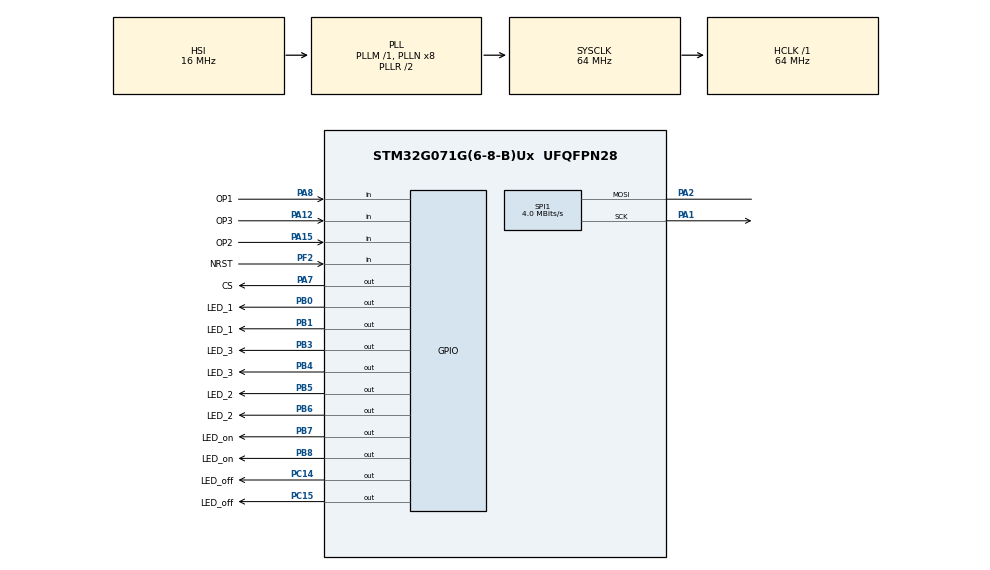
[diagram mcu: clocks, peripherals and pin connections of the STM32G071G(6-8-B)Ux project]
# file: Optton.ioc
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Dma.Request0=SPI1_TX
Dma.SPI1_TX.0.Direction=DMA_MEMORY_TO_PERIPH
Dma.SPI1_TX.0.EventEnable=DISABLE
Dma.SPI1_TX.0.Instance=DMA1_Channel1
Dma.SPI1_TX.0.MemDataAlignment=DMA_MDATAALIGN_BYTE
Dma.SPI1_TX.0.MemInc=DMA_MINC_ENABLE
Dma.SPI1_TX.0.Mode=DMA_NORMAL
Dma.SPI1_TX.0.PeriphDataAlignment=DMA_PDATAALIGN_BYTE
Dma.SPI1_TX.0.PeriphInc=DMA_PINC_DISABLE
Dma.SPI1_TX.0.Polarity=HAL_DMAMUX_REQ_GEN_RISING
Dma.SPI1_TX.0.Priority=DMA_PRIORITY_LOW
Dma.SPI1_TX.0.RequestNumber=1
Dma.SPI1_TX.0.SignalID=NONE
Dma.SPI1_TX.0.SyncEnable=DISABLE
Dma.SPI1_TX.0.SyncPolarity=HAL_DMAMUX_SYNC_NO_EVENT
Dma.SPI1_TX.0.SyncRequestNumber=1
Dma.SPI1_TX.0.SyncSignalID=NONE
FREERTOS.Tasks01=defaultTask,24,128,StartDefaultTask,Default,NULL,Dynamic,NULL,NULL;MCP23Task,24,128,StartTask02,Default,NULL,Dynamic,NULL,NULL
Mcu.Family=STM32G0
Mcu.Name=STM32G071G(6-8-B)Ux
Mcu.Package=UFQFPN28
NVIC.DMA1_Channel1_IRQn=true\:3\:0\:false\:false\:true\:true\:false\:true\:true
NVIC.SPI1_IRQn=true\:3\:0\:false\:false\:true\:true\:true\:true\:true
PA1.Mode=Simplex_Bidirectional_Master
PA1.Signal=SPI1_SCK
PA12\ [PA10].GPIO_Label=OP3
PA12\ [PA10].Signal=GPIO_Input
PA13.Mode=Serial_Wire
PA13.Signal=SYS_SWDIO
PA14-BOOT0.Mode=Serial_Wire
PA14-BOOT0.Signal=SYS_SWCLK
PA15.GPIO_Label=OP2
PA15.Signal=GPIO_Input
PA2.Mode=Simplex_Bidirectional_Master
PA2.Signal=SPI1_MOSI
PA7.GPIO_Label=CS
PA7.Signal=GPIO_Output
PA8.GPIO_Label=OP1
PA8.Signal=GPIO_Input
PB0.GPIO_Label=LED_1
PB0.Signal=GPIO_Output
PB1.GPIO_Label=LED_1
PB1.Signal=GPIO_Output
PB3.GPIO_Label=LED_3
PB3.Signal=GPIO_Output
PB4.GPIO_Label=LED_3
PB4.Signal=GPIO_Output
PB5.GPIO_Label=LED_2
PB5.Signal=GPIO_Output
PB6.GPIO_Label=LED_2
PB6.Signal=GPIO_Output
PB7.GPIO_Label=LED_on
PB7.Signal=GPIO_Output
PB8.GPIO_Label=LED_on
PB8.Signal=GPIO_Output
PC14-OSC32_IN\ (PC14).GPIO_Label=LED_off
PC14-OSC32_IN\ (PC14).Signal=GPIO_Output
PC15-OSC32_OUT\ (PC15).GPIO_Label=LED_off
PC15-OSC32_OUT\ (PC15).Signal=GPIO_Output
PF2\ -\ NRST.GPIO_Label=NRST
PF2\ -\ NRST.Signal=GPIO_Input
ProjectManager.HeapSize=0x200
ProjectManager.StackSize=0x400
ProjectManager.TargetToolchain=STM32CubeIDE
RCC.ADCFreq_Value=64000000
RCC.AHBFreq_Value=64000000
RCC.CortexFreq_Value=64000000
RCC.EXTERNAL_CLOCK_VALUE=48000
RCC.HCLKFreq_Value=64000000
RCC.HSE_VALUE=8000000
RCC.HSI_VALUE=16000000
RCC.LSE_VALUE=32768
RCC.SYSCLKFreq_VALUE=64000000
RCC.SYSCLKSource=RCC_SYSCLKSOURCE_PLLCLK
RCC.VCOOutputFreq_Value=128000000
SPI1.BaudRatePrescaler=SPI_BAUDRATEPRESCALER_16
SPI1.CLKPolarity=SPI_POLARITY_LOW
SPI1.CalculateBaudRate=4.0 MBits/s
SPI1.DataSize=SPI_DATASIZE_8BIT
SPI1.Direction=SPI_DIRECTION_1LINE
SPI1.FirstBit=SPI_FIRSTBIT_MSB
SPI1.Mode=SPI_MODE_MASTER
SPI1.NSSPMode=SPI_NSS_PULSE_DISABLE
SPI1.VirtualType=VM_MASTER
VP_FREERTOS_VS_CMSIS_V2.Mode=CMSIS_V2
board=custom

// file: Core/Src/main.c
/* USER CODE BEGIN Header */

/*						########## OPTTON ##############
 * in The Main.c Use include Library TT.C To Make Working by OPTTON SENSOR AND DEMO JIG and USE FreeRTOS for 2 Task
 *
 * 1. Sensor Module working       #defaultTask#
 *
 * 2. Send SPI Data 			  #MCP23Task#
 *
 * *  Created on: Mar 24, 2025
 *      Author: Thaweechock.M
 * */
/**
  ******************************************************************************
  * @file           : main.c
  * @brief          : Main program body
  ******************************************************************************
  * @attention
  *
  * Copyright (c) 2025 STMicroelectronics.
  * All rights reserved.
  *
  * This software is licensed under terms that can be found in the LICENSE file
  * in the root directory of this software component.
  * If no LICENSE file comes with this software, it is provided AS-IS.
  *
  ******************************************************************************
  */
/* USER CODE END Header */
#include "main.h"
#include "cmsis_os.h"

/* USER CODE BEGIN Includes */
#include "TT.h"
/* USER CODE END Includes */

SPI_HandleTypeDef hspi1;
DMA_HandleTypeDef hdma_spi1_tx;

/* Definitions for defaultTask */
osThreadId_t defaultTaskHandle;
const osThreadAttr_t defaultTask_attributes = {									// STAR make Task 1 OPTTON
  .name = "defaultTask",
  .priority = (osPriority_t) osPriorityNormal,
  .stack_size = 128 * 4
};
/* Definitions for MCP23Task */
osThreadId_t MCP23TaskHandle;
const osThreadAttr_t MCP23Task_attributes = {									// STAR make Task 2 SPI SEND DATA
  .name = "MCP23Task",
  .priority = (osPriority_t) osPriorityNormal,
  .stack_size = 128 * 4
};

void SystemClock_Config(void);
static void MX_GPIO_Init(void);
static void MX_DMA_Init(void);
static void MX_SPI1_Init(void);
void StartDefaultTask(void *argument);
void StartTask02(void *argument);

int main(void)
{

  /* MCU Configuration--------------------------------------------------------*/

  /* Reset of all peripherals, Initializes the Flash interface and the Systick. */
  HAL_Init();

  /* Configure the system clock */
  SystemClock_Config();

  /* Initialize all configured peripherals */
  MX_GPIO_Init();
  MX_DMA_Init();
  MX_SPI1_Init();
  /* USER CODE BEGIN 2 */
  MCP23S17_Init();
  //WaitForStart();
  /* USER CODE END 2 */

  /* Init scheduler */
  osKernelInitialize();

  /* Create the thread(s) */
  /* creation of defaultTask */
  defaultTaskHandle = osThreadNew(StartDefaultTask, NULL, &defaultTask_attributes);

  /* creation of MCP23Task */
  MCP23TaskHandle = osThreadNew(StartTask02, NULL, &MCP23Task_attributes);

  /* Start scheduler */
  osKernelStart();

  /* We should never get here as control is now taken by the scheduler */

  /* Infinite loop */
  while (1)
  {

  }
}

void SystemClock_Config(void)
{
  RCC_OscInitTypeDef RCC_OscInitStruct = {0};
  RCC_ClkInitTypeDef RCC_ClkInitStruct = {0};

  /** Configure the main internal regulator output voltage
  */
  HAL_PWREx_ControlVoltageScaling(PWR_REGULATOR_VOLTAGE_SCALE1);

  /** Initializes the RCC Oscillators according to the specified parameters
  * in the RCC_OscInitTypeDef structure.
  */
  RCC_OscInitStruct.OscillatorType = RCC_OSCILLATORTYPE_HSI;
  RCC_OscInitStruct.HSIState = RCC_HSI_ON;
  RCC_OscInitStruct.HSIDiv = RCC_HSI_DIV1;
  RCC_OscInitStruct.HSICalibrationValue = RCC_HSICALIBRATION_DEFAULT;
  RCC_OscInitStruct.PLL.PLLState = RCC_PLL_ON;
  RCC_OscInitStruct.PLL.PLLSource = RCC_PLLSOURCE_HSI;
  RCC_OscInitStruct.PLL.PLLM = RCC_PLLM_DIV1;
  RCC_OscInitStruct.PLL.PLLN = 8;
  RCC_OscInitStruct.PLL.PLLP = RCC_PLLP_DIV2;
  RCC_OscInitStruct.PLL.PLLQ = RCC_PLLQ_DIV2;
  RCC_OscInitStruct.PLL.PLLR = RCC_PLLR_DIV2;
  if (HAL_RCC_OscConfig(&RCC_OscInitStruct) != HAL_OK)
  {
    Error_Handler();
  }

  /** Initializes the CPU, AHB and APB buses clocks
  */
  RCC_ClkInitStruct.ClockType = RCC_CLOCKTYPE_HCLK|RCC_CLOCKTYPE_SYSCLK
                              |RCC_CLOCKTYPE_PCLK1;
  RCC_ClkInitStruct.SYSCLKSource = RCC_SYSCLKSOURCE_PLLCLK;
  RCC_ClkInitStruct.AHBCLKDivider = RCC_SYSCLK_DIV1;
  RCC_ClkInitStruct.APB1CLKDivider = RCC_HCLK_DIV1;

  if (HAL_RCC_ClockConfig(&RCC_ClkInitStruct, FLASH_LATENCY_2) != HAL_OK)
  {
    Error_Handler();
  }
}

static void MX_SPI1_Init(void)
{

  /* USER CODE BEGIN SPI1_Init 0 */
	__HAL_RCC_SPI1_CLK_ENABLE(); // เ�?ิด Clock �?ห�? SPI1
	__HAL_RCC_GPIOA_CLK_ENABLE();
  /* USER CODE END SPI1_Init 0 */

  /* SPI1 parameter configuration*/
  hspi1.Instance = SPI1;
  hspi1.Init.Mode = SPI_MODE_MASTER;
  hspi1.Init.Direction = SPI_DIRECTION_1LINE;
  hspi1.Init.DataSize = SPI_DATASIZE_8BIT;
  hspi1.Init.CLKPolarity = SPI_POLARITY_LOW;
  hspi1.Init.CLKPhase = SPI_PHASE_1EDGE;
  hspi1.Init.NSS = SPI_NSS_SOFT;
  hspi1.Init.BaudRatePrescaler = SPI_BAUDRATEPRESCALER_16;
  hspi1.Init.FirstBit = SPI_FIRSTBIT_MSB;
  hspi1.Init.TIMode = SPI_TIMODE_DISABLE;
  hspi1.Init.CRCCalculation = SPI_CRCCALCULATION_DISABLE;
  hspi1.Init.CRCPolynomial = 7;
  hspi1.Init.CRCLength = SPI_CRC_LENGTH_DATASIZE;
  hspi1.Init.NSSPMode = SPI_NSS_PULSE_DISABLE;
  if (HAL_SPI_Init(&hspi1) != HAL_OK)
  {
    Error_Handler();
  }

}

static void MX_DMA_Init(void)
{

  /* DMA controller clock enable */
  __HAL_RCC_DMA1_CLK_ENABLE();

  /* DMA interrupt init */
  /* DMA1_Channel1_IRQn interrupt configuration */
  HAL_NVIC_SetPriority(DMA1_Channel1_IRQn, 3, 0);
  HAL_NVIC_EnableIRQ(DMA1_Channel1_IRQn);

}

static void MX_GPIO_Init(void)
{
  GPIO_InitTypeDef GPIO_InitStruct = {0};

  /* GPIO Ports Clock Enable */
  __HAL_RCC_GPIOC_CLK_ENABLE();
  __HAL_RCC_GPIOF_CLK_ENABLE();
  __HAL_RCC_GPIOA_CLK_ENABLE();
  __HAL_RCC_GPIOB_CLK_ENABLE();

  /*Configure GPIO pin Output Level */
  HAL_GPIO_WritePin(GPIOC, LED_off_Pin|LED_offC15_Pin, GPIO_PIN_RESET);

  /*Configure GPIO pin Output Level */
  HAL_GPIO_WritePin(CS_GPIO_Port, CS_Pin, GPIO_PIN_RESET);

  /*Configure GPIO pin Output Level */
  HAL_GPIO_WritePin(GPIOB, LED_1_Pin|LED_1B1_Pin|LED_3_Pin|LED_3B4_Pin
                          |LED_2_Pin|LED_2B6_Pin|LED_on_Pin|LED_onB8_Pin, GPIO_PIN_RESET);

  /*Configure GPIO pins : LED_off_Pin LED_offC15_Pin */
  GPIO_InitStruct.Pin = LED_off_Pin|LED_offC15_Pin;
  GPIO_InitStruct.Mode = GPIO_MODE_OUTPUT_PP;
  GPIO_InitStruct.Pull = GPIO_NOPULL;
  GPIO_InitStruct.Speed = GPIO_SPEED_FREQ_LOW;
  HAL_GPIO_Init(GPIOC, &GPIO_InitStruct);

  /*Configure GPIO pin : NRST_Pin */
  GPIO_InitStruct.Pin = NRST_Pin;
  GPIO_InitStruct.Mode = GPIO_MODE_INPUT;
  GPIO_InitStruct.Pull = GPIO_NOPULL;
  HAL_GPIO_Init(NRST_GPIO_Port, &GPIO_InitStruct);

  /*Configure GPIO pin : CS_Pin */
  GPIO_InitStruct.Pin = CS_Pin;
  GPIO_InitStruct.Mode = GPIO_MODE_OUTPUT_PP;
  GPIO_InitStruct.Pull = GPIO_NOPULL;
  GPIO_InitStruct.Speed = GPIO_SPEED_FREQ_LOW;
  HAL_GPIO_Init(CS_GPIO_Port, &GPIO_InitStruct);

  /*Configure GPIO pins : LED_1_Pin LED_1B1_Pin LED_3_Pin LED_3B4_Pin
                           LED_2_Pin LED_2B6_Pin LED_on_Pin LED_onB8_Pin */
  GPIO_InitStruct.Pin = LED_1_Pin|LED_1B1_Pin|LED_3_Pin|LED_3B4_Pin
                          |LED_2_Pin|LED_2B6_Pin|LED_on_Pin|LED_onB8_Pin;
  GPIO_InitStruct.Mode = GPIO_MODE_OUTPUT_PP;
  GPIO_InitStruct.Pull = GPIO_NOPULL;
  GPIO_InitStruct.Speed = GPIO_SPEED_FREQ_LOW;
  HAL_GPIO_Init(GPIOB, &GPIO_InitStruct);

  /*Configure GPIO pins : OP1_Pin OP3_Pin OP2_Pin */
  GPIO_InitStruct.Pin = OP1_Pin|OP3_Pin|OP2_Pin;
  GPIO_InitStruct.Mode = GPIO_MODE_INPUT;
  GPIO_InitStruct.Pull = GPIO_NOPULL;
  HAL_GPIO_Init(GPIOA, &GPIO_InitStruct);

/* USER CODE BEGIN MX_GPIO_Init_2 */
  GPIO_InitStruct.Pin = GPIO_PIN_10 | GPIO_PIN_12;
  GPIO_InitStruct.Mode = GPIO_MODE_INPUT;
  GPIO_InitStruct.Pull = GPIO_NOPULL;
  HAL_GPIO_Init(GPIOA, &GPIO_InitStruct);
/* USER CODE END MX_GPIO_Init_2 */
}

void StartDefaultTask(void *argument)								// TASK_1 "SENSOR PATTERN"
{
  /* USER CODE BEGIN 5 */
  /* Infinite loop */
  for(;;)
  {
	ProcessPattern(); 												//#### PATTERN LOOP ####
  }
  /* USER CODE END 5 */
}

void StartTask02(void *argument)									// TASK_2 "MCP data Send"
{
  /* USER CODE BEGIN StartTask02 */
  /* Infinite loop */
  while(1)
  {
	Send_data(); 													//#### SEND Data SPI LOOP ####
  }
  /* USER CODE END StartTask02 */
}

void Error_Handler(void)
{
  __disable_irq();
  while (1)
  {
  }
}
